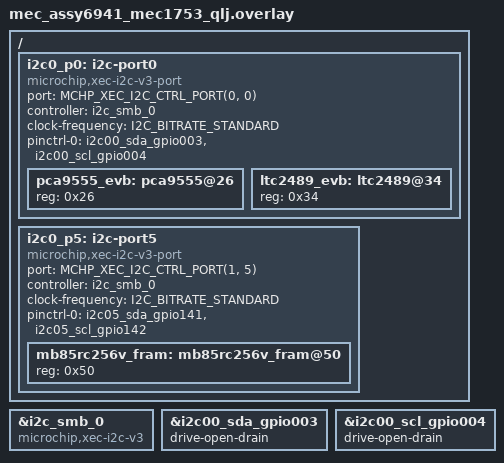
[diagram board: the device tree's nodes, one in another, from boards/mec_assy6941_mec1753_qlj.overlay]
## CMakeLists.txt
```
# Copyright (c) 2022 Microchip Technology Inc.
#
# SPDX-License-Identifier: Apache-2.0
#
cmake_minimum_required(VERSION 3.20.0)

find_package(Zephyr REQUIRED HINTS $ENV{ZEPHYR_BASE})
project(microchip_evb_i2c_v3_sample)

FILE(GLOB app_sources src/*.c)
target_sources(app PRIVATE ${app_sources})
```

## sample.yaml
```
sample:
  description: Microchip MEC EVB I2C V3 port switching sample
  name: mec_assy6941_i2c_v3
tests:
  sample.board.microchip.evb.i2c_v3:
    harness: i2c
    platform_allow:
      - mec_assy6941/mec1653b_nsz
      - mec_assy6941/mec1753_qlj
    tags: i2c
    depends_on:
      - i2c
      - gpio
```

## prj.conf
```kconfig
# Enable config log
CONFIG_STDOUT_CONSOLE=y
CONFIG_LOG=y

CONFIG_I2C=y
# CONFIG_I2C_CALLBACK=y
# CONFIG_I2C_TARGET=y
# CONFIG_I2C_TARGET_BUFFER_MODE=y

CONFIG_PM=n
CONFIG_DEBUG=y
```

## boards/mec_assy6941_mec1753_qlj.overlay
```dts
/*
 * Copyright (c) 2026 Microchip Technology Inc.
 *
 * SPDX-License-Identifier: Apache-2.0
 */

/* mec_assy6941 EVB
 * JP15 7-8 GPIO004 as I2C00_SCL
 * JP15 4-5 GPIO003 as I2C00_SDA
 * JP27 31-32 GPIO004 as I2C00_SCL
 * JP27 34-35 GPIO003 as I2C00_SDA
 *
 * JP20 1-2 GPIO144 as I2C04_SCL
 * JP20 4-5 GPIO143 as I2C04_SDA
 * JP21 13-14 GPIO144 as I2C04_SCL
 * JP21 25-26 GPIO143 as I2C04_SDA
 *
 * JP70 19-20 ON enable 7.5K pull-up to VTR1
 * JP70 21-22 ON enable 7.5K pull-up to VTR1
 * JP71 25-26 OFF no 7.5K pull-up
 * JP71 27-28 OFF no 7.5K pull-up
 * I2C Port 0
 *   J12 1x6
 *	pin 1 = I2C00_SCL/GPIO004
 *	pin 2 = GND
 *	pin 3 = I2C00_SDA/GPIO003
 *	pin 4 = GND
 *	pin 5 = VTR1
 *	pin 6 = GND
 * I2C Port 4
 *   J17 1x6
 *	pin 1 = I2C04_SCL/GPIO144
 *	pin 2 = GND
 *	pin 3 = I2C04_SDA/GPIO143
 *	pin 4 = GND
 *	pin 5 = VTR1
 *	pin 6 = GND
 */

/* original V2 driver */
/*
&i2c_smb_0 {
	compatible = "microchip,xec-i2c-v2";
	clock-frequency = <I2C_BITRATE_STANDARD>;
	port-sel = <0>;
	pinctrl-0 = <&i2c00_sda_gpio003 &i2c00_scl_gpio004>;
	pinctrl-names = "default";
	scl-gpios = <MCHP_GPIO_DECODE_004 GPIO_OPEN_DRAIN>;
	sda-gpios = <MCHP_GPIO_DECODE_003 GPIO_OPEN_DRAIN>;
	status = "okay";

	eeprom0: eeprom@54 {
		compatible = "zephyr,i2c-target-eeprom";
		reg = <0x54>;
		address-width = <16>;
		size = <1024>;
	};
};

&i2c_smb_1 {
	compatible = "microchip,xec-i2c-v2";
	clock-frequency = <I2C_BITRATE_STANDARD>;
	port-sel = <4>;
	pinctrl-0 = <&i2c04_sda_gpio143 &i2c04_scl_gpio144>;
	pinctrl-names = "default";
	scl-gpios = <MCHP_GPIO_DECODE_144 GPIO_OPEN_DRAIN>;
	sda-gpios = <MCHP_GPIO_DECODE_143 GPIO_OPEN_DRAIN>;
	status = "okay";

	eeprom1: eeprom@56 {
		compatible = "zephyr,i2c-target-eeprom";
		reg = <0x56>;
		address-width = <16>;
		size = <1024>;
	};
};
*/

#include <zephyr/dt-bindings/i2c/i2c.h>
#include <zephyr/dt-bindings/i2c/mchp-xec-i2c.h>

/* V3 driver includes port switching requiring a different DT
 * V3 driver only supports version 3.8 I2C_SMB controller in
 * MEC174x/5x/165xB and onwards.
 */

&i2c_smb_0 {
	compatible = "microchip,xec-i2c-v3";
	status = "okay";
	#address-cells = <1>;
	#size-cells = <0>;
/*
	i2c0_p0: i2c-port@0 {
		compatible = "microchip,xec-i2c-v3-port";
		#address-cells = <1>;
		#size-cells = <0>;
		reg = <0>;
		port = <MCHP_XEC_I2C_CTRL_PORT(0, 0)>;
		controller = <&i2c_smb_0>;
		clock-frequency = <I2C_BITRATE_STANDARD>;
		pinctrl-0 = <&i2c00_sda_gpio003 &i2c00_scl_gpio004>;
		pinctrl-names = "default";
		status = "okay";

		pca9555_evb: pca9555@26 {
			reg = <0x26>;
			status = "okay";
		};

		ltc2489_evb: ltc2489@34 {
			reg = <0x34>;
			status = "okay";
		};
	};

	i2c0_p5: i2c-port@5 {
		compatible = "microchip,xec-i2c-v3-port";
		#address-cells = <1>;
		#size-cells = <0>;
		reg = <5>;
		port = <MCHP_XEC_I2C_CTRL_PORT(1, 5)>;
		controller = <&i2c_smb_0>;
		clock-frequency = <I2C_BITRATE_STANDARD>;
		pinctrl-0 = <&i2c05_sda_gpio141 &i2c05_scl_gpio142>;
		pinctrl-names = "default";
		status = "okay";

		mb85rc256v_fram: mb85rc256v_fram@50 {
			reg = <0x50>;
			#io-channels-cells = <1>;
		};
	};
*/
};

/* Cannot use reg property in nodes who do not have a parent with actual
 * reg = <address length>;
 * Also cannot use unit @num syntax without reg!
 */

/ {
	i2c0_p0: i2c-port0 {
		compatible = "microchip,xec-i2c-v3-port";
		port = <MCHP_XEC_I2C_CTRL_PORT(0, 0)>;
		controller = <&i2c_smb_0>;
		clock-frequency = <I2C_BITRATE_STANDARD>;
		pinctrl-0 = <&i2c00_sda_gpio003 &i2c00_scl_gpio004>;
		pinctrl-names = "default";
		status = "okay";
		#address-cells = <1>;
		#size-cells = <0>;

		pca9555_evb: pca9555@26 {
			reg = <0x26>;
			status = "okay";
		};

		ltc2489_evb: ltc2489@34 {
			reg = <0x34>;
			status = "okay";
		};
	};

	i2c0_p5: i2c-port5 {
		compatible = "microchip,xec-i2c-v3-port";
		#address-cells = <1>;
		#size-cells = <0>;
		port = <MCHP_XEC_I2C_CTRL_PORT(1, 5)>;
		controller = <&i2c_smb_0>;
		clock-frequency = <I2C_BITRATE_STANDARD>;
		pinctrl-0 = <&i2c05_sda_gpio141 &i2c05_scl_gpio142>;
		pinctrl-names = "default";
		status = "okay";

		mb85rc256v_fram: mb85rc256v_fram@50 {
			reg = <0x50>;
			#io-channels-cells = <1>;
		};
	};
};


/*
&i2c_smb_1 {
	compatible = "microchip,xec-i2c-v3";
	status = "okay";
	#address-cells = <1>;
	#size-cells = <0>;

	i2c0_p4: i2c-port@5 {
		compatible = "microchip,xec-i2c-v3-port";
		#address-cells = <1>;
		#size-cells = <0>;
		reg = <5>;
		port = <MCHP_XEC_I2C_CTRL_PORT(1, 5)>;
		controller = <&i2c_smb_1>;
		clock-frequency = <I2C_BITRATE_STANDARD>;
		pinctrl-0 = <&i2c05_sda_gpio141 &i2c05_scl_gpio142>;
		pinctrl-names = "default";
		status = "okay";

		mb85rc256v_fram: mb85rc256v_fram@50 {
			reg = <0x50>;
			#io-channels-cells = <1>;
		};
	};
};
*/

&i2c00_sda_gpio003 {
	drive-open-drain;
};

&i2c00_scl_gpio004 {
	drive-open-drain;
};

/*
&i2c05_sda_gpio141 {
	drive-open-drain;
};

&i2c05_scl_gpio142 {
	drive-open-drain;
};
*/
```

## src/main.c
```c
/*
 * Copyright (c) 2026 Microchip Technology Inc.
 *
 * SPDX-License-Identifier: Apache-2.0
 */

#include <soc.h>
#include <string.h>
#include <zephyr/kernel.h>
#include <zephyr/device.h>
#include <zephyr/devicetree.h>
#include <zephyr/drivers/i2c.h>
#include <zephyr/dt-bindings/i2c/i2c.h>
#include <zephyr/dt-bindings/i2c/mchp-xec-i2c.h>

#include <zephyr/logging/log.h>
#include <zephyr/logging/log_ctrl.h>
LOG_MODULE_REGISTER(app, CONFIG_LOG_DEFAULT_LEVEL);

#define PCA9555_CMD_PORT0_IN  0
#define PCA9555_CMD_PORT1_IN  1u
#define PCA9555_CMD_PORT0_OUT 2u
#define PCA9555_CMD_PORT1_OUT 3u
#define PCA9555_CMD_PORT0_POL 4u
#define PCA9555_CMD_PORT1_POL 5u
#define PCA9555_CMD_PORT0_CFG 6u
#define PCA9555_CMD_PORT1_CFG 7u

#define I2C_SMB_GET_DEV(nid) DEVICE_DT_GET(nid),

static const struct device *i2c_smb_ctrls[] = {
	DT_FOREACH_STATUS_OKAY(microchip_xec_i2c_v3, I2C_SMB_GET_DEV)
};

/* Ports on the controllers */
static const struct device *i2c_smb_ports[] = {
	DT_FOREACH_STATUS_OKAY(microchip_xec_i2c_v3_port, I2C_SMB_GET_DEV)
};

#define PCA9555_EVB_NODE     DT_NODELABEL(pca9555_evb)
#define LTC2489_EVB_NODE     DT_NODELABEL(ltc2489_evb)
#define MB85RC256V_FRAM_NODE DT_NODELABEL(mb85rc256v_fram)

const struct i2c_dt_spec pca9555_spec = I2C_DT_SPEC_GET(PCA9555_EVB_NODE);
const struct i2c_dt_spec ltc2489_spec = I2C_DT_SPEC_GET(LTC2489_EVB_NODE);
const struct i2c_dt_spec mb_fram_spec = I2C_DT_SPEC_GET(MB85RC256V_FRAM_NODE);

#define I2C_MAX_MSGS 8
#define I2C_TX_BUF_SIZE 256
#define I2C_RX_BUF_SIZE 256

static struct i2c_msg msgs[I2C_MAX_MSGS];
static uint8_t i2c_tx_buf[I2C_TX_BUF_SIZE];
static uint8_t i2c_rx_buf[I2C_RX_BUF_SIZE];

static int pca9555_test1(const struct i2c_dt_spec *dts);
static int ltc2489_test1(const struct i2c_dt_spec *dts);
static int fram_test1(const struct i2c_dt_spec *dts);

int main(void)
{
	int ctrl_ready_count = 0;
	int port_ready_count = 0;
	int rc = 0;

	memset((void *)msgs, 0, sizeof(msgs));
	memset(i2c_tx_buf, 0x55, I2C_TX_BUF_SIZE);
	memset(i2c_rx_buf, 0xAA, I2C_RX_BUF_SIZE);

	for (size_t i = 0; i < ARRAY_SIZE(i2c_smb_ctrls); i++) {
		const struct device *ctrl_dev = i2c_smb_ctrls[i];

		if (ctrl_dev == NULL) {
			continue;
		}

		if (device_is_ready(ctrl_dev)) {
			ctrl_ready_count++;
			LOG_INF("I2C Controller device %s is ready", ctrl_dev->name);
		} else {
			LOG_ERR("I2C Controller device %s is NOT ready", ctrl_dev->name);
		}
	}

	for (size_t i = 0; i < ARRAY_SIZE(i2c_smb_ports); i++) {
		const struct device *port_dev = i2c_smb_ports[i];

		if (port_dev == NULL) {
			continue;
		}

		if (device_is_ready(port_dev)) {
			port_ready_count++;
			LOG_INF("I2C Port device %s is ready", port_dev->name);
		} else {
			LOG_ERR("I2C Port device %s is NOT ready", port_dev->name);
		}
	}

	log_flush();

	if ((ctrl_ready_count != ARRAY_SIZE(i2c_smb_ctrls)) ||
	    (port_ready_count != ARRAY_SIZE(i2c_smb_ports))) {
		LOG_ERR("Skipping tests since some or all drivers are not ready");
		goto app_exit;
	}

	LOG_INF("Test communication with PCA9555");
	rc = pca9555_test1(&pca9555_spec);
	if (rc == 0) {
		LOG_INF("PCA9555 test 1 PASS");
	} else if (rc == -ENOTSUP) {
		LOG_INF("PCA9555 test1 not implemented");
	} else {
		LOG_ERR("PCA9555 test 1 FAIL (%d)", rc);
	}

	LOG_INF("Test communication with LTC2489");
	rc = ltc2489_test1(&ltc2489_spec);
	if (rc == 0) {
		LOG_INF("LTC2489 test 1 PASS");
	} else if (rc == -ENOTSUP) {
		LOG_INF("LTC2489 test 1 not implemented");
	} else {
		LOG_ERR("LTC2489 test 1 FAIL (%d)", rc);
	}

	LOG_INF("Test communication with FRAM");
	rc = fram_test1(&mb_fram_spec);
	if (rc == 0) {
		LOG_INF("FRAM test 1 PASS");
	} else if (rc == -ENOTSUP) {
		LOG_INF("FRAM test 1 not implemented");
	} else {
		LOG_ERR("FRAM test 1 FAIL (%d)", rc);
	}

app_exit:
	LOG_INF("Program End");
	log_flush();

	return 0;
}

static int pca9555_test1(const struct i2c_dt_spec *dts)
{
	int rc = -ENOTSUP;

	if (dts == NULL) {
		return -EINVAL;
	}

	memset(i2c_tx_buf, 0x55, sizeof(i2c_tx_buf));
	memset(i2c_rx_buf, 0xAA, sizeof(i2c_rx_buf));

	i2c_tx_buf[0] = PCA9555_CMD_PORT0_IN;

	rc = i2c_write_read_dt(dts, i2c_tx_buf, 1U, i2c_rx_buf, 2U);
	if (rc != 0) {
		return rc;
	}

	LOG_INF("PCA9555 read ports 0x%0x 0x%0x", i2c_rx_buf[0], i2c_rx_buf[1]);

	return rc;
}

static int ltc2489_test1(const struct i2c_dt_spec *dts)
{
	int rc = -ENOTSUP;

	if (dts == NULL) {
		return -EINVAL;
	}

	return rc;
}

static int fram_test1(const struct i2c_dt_spec *dts)
{
	int rc = -ENOTSUP;

	if (dts == NULL) {
		return -EINVAL;
	}

	memset(i2c_tx_buf, 0x55, sizeof(i2c_tx_buf));
	memset(i2c_rx_buf, 0xAA, sizeof(i2c_rx_buf));

	i2c_tx_buf[0] = 0x43U;
	i2c_tx_buf[1] = 0x21U;
	i2c_tx_buf[2] = 0x01U;
	i2c_tx_buf[3] = 0x02U;
	i2c_tx_buf[4] = 0x03U;
	i2c_tx_buf[5] = 0x04U;

	rc = i2c_write_dt(dts, i2c_tx_buf, 6U);
	if (rc != 0) {
		return rc;
	}

	i2c_tx_buf[0] = 0x43U;
	i2c_tx_buf[1] = 0x21U;

	rc = i2c_write_read_dt(dts, i2c_tx_buf, 2U, i2c_rx_buf, 4U);
	if (rc != 0) {
		return rc;
	}

	rc = memcmp(&i2c_tx_buf[2], i2c_rx_buf, 4U);
	if (rc != 0) {
		rc = -EPERM;
	}

	return rc;
}
```
